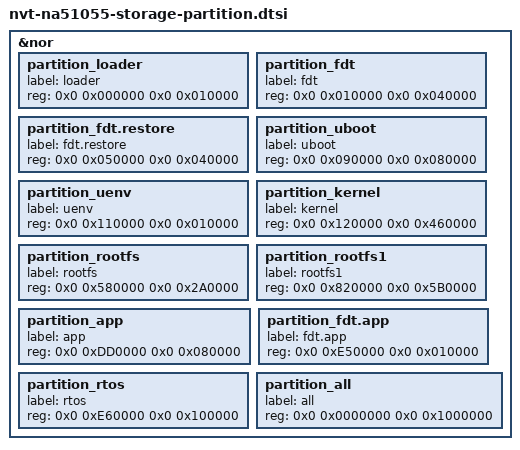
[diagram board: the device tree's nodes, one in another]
/*
 * Novatek Ltd. NA51055 BSP part of dts
 *
 * Cortex-A9
 *
 */

&nor {
	partition_loader {      label = "loader";       reg = <0x0 0x000000  0x0 0x010000>; }; /* Fixed */
	partition_fdt {	        label = "fdt";	        reg = <0x0 0x010000  0x0 0x040000>; }; /* Fixed */
	partition_fdt.restore {	label = "fdt.restore";	reg = <0x0 0x050000  0x0 0x040000>; }; /* Fixed */
	partition_uboot {       label = "uboot";        reg = <0x0 0x090000  0x0 0x080000>; };
	partition_uenv {        label = "uenv";         reg = <0x0 0x110000  0x0 0x010000>; };
	partition_kernel {      label = "kernel";       reg = <0x0 0x120000  0x0 0x460000>; };
	partition_rootfs {      label = "rootfs";       reg = <0x0 0x580000  0x0 0x2A0000>; };
	partition_rootfs1 {     label = "rootfs1";      reg = <0x0 0x820000  0x0 0x5B0000>; };
	partition_app {         label = "app";          reg = <0x0 0xDD0000  0x0 0x080000>; };
	partition_fdt.app {     label = "fdt.app";      reg = <0x0 0xE50000  0x0 0x010000>; };
	partition_rtos {        label = "rtos";         reg = <0x0 0xE60000  0x0 0x100000>; };
	partition_all {         label = "all";          reg = <0x0 0x0000000 0x0 0x1000000>; };
};
